# MSPM0G310X register map
Vendor: Texas Instruments; File version: This preliminary header file does not have a version number - build date: 2024-04-29 21:43:54
CPU: CM0 r0p1, little endian, MPU, no FPU, 3 interrupt priority bits
Registers are 32-bit, read-write, reset 0x0 unless marked. A register's access mark holds for its fields unless they carry their own. Offsets are from the block's base; [hi:lo] are bit positions; lines under a group give offsets from that group; {n}, {i} and the like mark numbered series; 'fields as' and 'values as' point back to an identical list.

## EVENTLP — PERIPHERALREGION
Base 0x400C9000
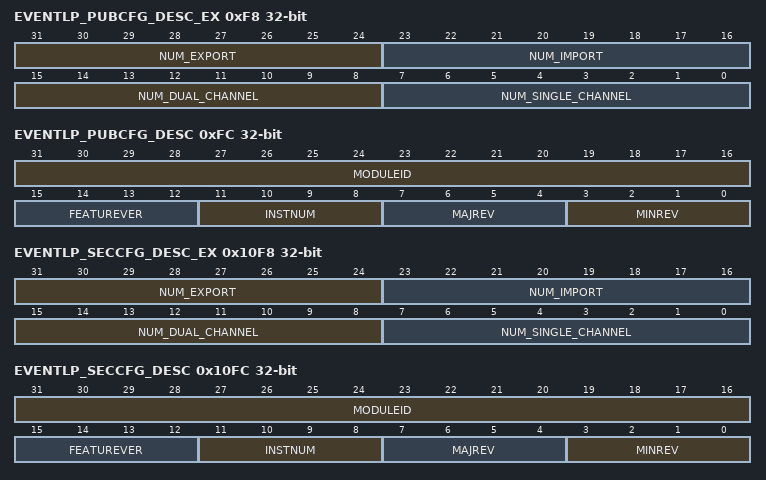
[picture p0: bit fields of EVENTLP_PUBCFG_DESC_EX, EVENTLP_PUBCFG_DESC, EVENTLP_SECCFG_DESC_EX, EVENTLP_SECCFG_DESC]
0xF8 EVENTLP_PUBCFG_DESC_EX ro — Extended Module Description
  [31:24] NUM_EXPORT — Number of export ports available in this EventManager instantiation
  [23:16] NUM_IMPORT — Number of import ports available in this EventManager instantiation
  [15:8] NUM_DUAL_CHANNEL — Number of dual channels contained in this instance of event manager
  [7:0] NUM_SINGLE_CHANNEL — Number of single channels contained in this instance of event manager
0xFC EVENTLP_PUBCFG_DESC ro — Module Description
  [31:16] MODULEID — Module identification contains a unique peripheral identification number. The assignments are maintained in a central database for all of the platform modules to ensure uniqueness.
  [15:12] FEATUREVER — Feature Set for the module *instance*
  [11:8] INSTNUM — Instance Number within the device. This will be a parameter to the RTL for modules that can have multiple instances
  [7:4] MAJREV — Major rev of the IP
  [3:0] MINREV — Minor rev of the IP
{0x100+0x80*i} EVENTLP_PUBCFG_FSUB[{i}] (i=0..0) group
  {0x0+4j} EVENTLP_PUBCFG_FSUB_PORT[{j}] (j=0..31) — Subscriber channel ID register
    [7:0] CHANID — Channel ID for subscriber to connect to
{0x300+0x68*i} EVENTLP_PUBCFG_FPUB[{i}] (i=0..0) group
  {0x0+4j} EVENTLP_PUBCFG_FPUB_PORT[{j}] (j=0..25) — Publisher channel ID register
    [7:0] CHANID — Channel ID for publisher to connect to
{0x500+4i} EVENTLP_PUBCFG_EXPORT[{i}] (i=0..0) group
  0x00 EVENTLP_PUBCFG_EXPORT_PORT — Export channel ID register
    [7:0] CHANID — Channel ID for export side to connect to
{0x700+4i} EVENTLP_PUBCFG_IMPORT[{i}] (i=0..0) group
  0x00 EVENTLP_PUBCFG_IMPORT_PORT — Import channel ID registe
    [7:0] CHANID — Channel ID for import side to connect to
{0x900+0x80*i} EVENTLP_PUBCFG_CPU_CONNECT[{i}] (i=0..0) group
  {0x0+4j} EVENTLP_PUBCFG_CPU_NUM[{j}] (j=0..31) — CPU connect register
    [1] CPUSS0_CONN — CPUSS0 connect bit.
      0=UNCONNECTED (The CPU is not connected.); 1=CONNECTED (The CPU is connected.)
0x10F8 EVENTLP_SECCFG_DESC_EX ro — Extended Module Description
  fields as EVENTLP_PUBCFG_DESC_EX
0x10FC EVENTLP_SECCFG_DESC ro — Module Description
  fields as EVENTLP_PUBCFG_DESC
{0x1100+0x20*i} EVENTLP_SECCFG_FSUB[{i}] (i=0..0) group
  {0x0+j} EVENTLP_SECCFG_FSUB_PORT[{j}] (j=0..31) 8-bit — Subscriber channel ID register
    [7:0] CHANID — Channel ID for subscriber to connect to
{0x1180+0x1A*i} EVENTLP_SECCFG_FPUB[{i}] (i=0..0) group
  {0x0+j} EVENTLP_SECCFG_FPUB_PORT[{j}] (j=0..25) 8-bit — Publisher channel ID register
    [7:0] CHANID — Channel ID for publisher to connect to
{0x1200+i} EVENTLP_SECCFG_EXPORT[{i}] (i=0..0) group
  0x00 EVENTLP_SECCFG_EXPORT_PORT 8-bit — Export channel ID register
    [7:0] CHANID — Channel ID for export side to connect to
{0x1280+i} EVENTLP_SECCFG_IMPORT[{i}] (i=0..0) group
  0x00 EVENTLP_SECCFG_IMPORT_PORT 8-bit — Import channel ID registe
    [7:0] CHANID — Channel ID for import side to connect to
{0x1300+0x20*i} EVENTLP_SECCFG_CPU_CONNECT[{i}] (i=0..0) group
  {0x0+j} EVENTLP_SECCFG_CPU_NUM[{j}] (j=0..31) 8-bit — CPU connect register
    fields as EVENTLP_PUBCFG_CPU_CONNECT[0].EVENTLP_PUBCFG_CPU_NUM[0]
0x1400 EVENTLP_CTL 8-bit — Event Manager control register
  [3:0] OVRWR_EN — Enable overwrite of config even if resources are already configured. By default, a configuration cannot be overwritten.
    5=DISABLE (Overwrite is disabled. Mode is same as in UNASG aperture.); 10=ENABLED (Ovewrite is enabled)
{0x1C00+0x400*i} EVENTLP_LMGMT_SFTYDIAG[{i}] (i=0..0) group
  0xEC EVENTLP_DIAGPAR192 wo — Diagnostic Parity Register 768
    [0] ASSERTDIAG — Writing a 1 will cause the safety diagnostic logic to generate a diagnostic check.
      0=NO_EFFECT; 1=START (Generate diagnostic check)
  0xF0 EVENTLP_DIAGPAR191 wo — Diagnostic Parity Register 191
    fields as EVENTLP_LMGMT_SFTYDIAG[0].EVENTLP_DIAGPAR192
  0xF4 EVENTLP_DIAGPAR190 wo — Diagnostic Parity Register 190
    fields as EVENTLP_LMGMT_SFTYDIAG[0].EVENTLP_DIAGPAR192
  0xF8 EVENTLP_DIAGPAR189 wo — Diagnostic Parity Register 189
    fields as EVENTLP_LMGMT_SFTYDIAG[0].EVENTLP_DIAGPAR192
  0xFC EVENTLP_DIAGPAR188 wo — Diagnostic Parity Register 188
    fields as EVENTLP_LMGMT_SFTYDIAG[0].EVENTLP_DIAGPAR192
  0x100 EVENTLP_DIAGPAR187 wo — Diagnostic Parity Register 187
    fields as EVENTLP_LMGMT_SFTYDIAG[0].EVENTLP_DIAGPAR192
  0x104 EVENTLP_DIAGPAR186 wo — Diagnostic Parity Register 186
    fields as EVENTLP_LMGMT_SFTYDIAG[0].EVENTLP_DIAGPAR192
  0x108 EVENTLP_DIAGPAR185 wo — Diagnostic Parity Register 185
    fields as EVENTLP_LMGMT_SFTYDIAG[0].EVENTLP_DIAGPAR192
  0x10C EVENTLP_DIAGPAR184 wo — Diagnostic Parity Register 184
    fields as EVENTLP_LMGMT_SFTYDIAG[0].EVENTLP_DIAGPAR192
  0x110 EVENTLP_DIAGPAR183 wo — Diagnostic Parity Register 183
    fields as EVENTLP_LMGMT_SFTYDIAG[0].EVENTLP_DIAGPAR192
  0x114 EVENTLP_DIAGPAR182 wo — Diagnostic Parity Register 182
    fields as EVENTLP_LMGMT_SFTYDIAG[0].EVENTLP_DIAGPAR192
  0x118 EVENTLP_DIAGPAR181 wo — Diagnostic Parity Register 181
    fields as EVENTLP_LMGMT_SFTYDIAG[0].EVENTLP_DIAGPAR192
  0x11C EVENTLP_DIAGPAR180 wo — Diagnostic Parity Register 180
    fields as EVENTLP_LMGMT_SFTYDIAG[0].EVENTLP_DIAGPAR192
  0x120 EVENTLP_DIAGPAR179 wo — Diagnostic Parity Register 179
    fields as EVENTLP_LMGMT_SFTYDIAG[0].EVENTLP_DIAGPAR192
  0x124 EVENTLP_DIAGPAR178 wo — Diagnostic Parity Register 178
    fields as EVENTLP_LMGMT_SFTYDIAG[0].EVENTLP_DIAGPAR192
  0x128 EVENTLP_DIAGPAR177 wo — Diagnostic Parity Register 177
    fields as EVENTLP_LMGMT_SFTYDIAG[0].EVENTLP_DIAGPAR192
  0x12C EVENTLP_DIAGPAR176 wo — Diagnostic Parity Register 176
    fields as EVENTLP_LMGMT_SFTYDIAG[0].EVENTLP_DIAGPAR192
  0x130 EVENTLP_DIAGPAR175 wo — Diagnostic Parity Register 175
    fields as EVENTLP_LMGMT_SFTYDIAG[0].EVENTLP_DIAGPAR192
  0x134 EVENTLP_DIAGPAR174 wo — Diagnostic Parity Register 174
    fields as EVENTLP_LMGMT_SFTYDIAG[0].EVENTLP_DIAGPAR192
  0x138 EVENTLP_DIAGPAR173 wo — Diagnostic Parity Register 173
    fields as EVENTLP_LMGMT_SFTYDIAG[0].EVENTLP_DIAGPAR192
  0x13C EVENTLP_DIAGPAR172 wo — Diagnostic Parity Register 172
    fields as EVENTLP_LMGMT_SFTYDIAG[0].EVENTLP_DIAGPAR192
  0x140 EVENTLP_DIAGPAR171 wo — Diagnostic Parity Register 171
    fields as EVENTLP_LMGMT_SFTYDIAG[0].EVENTLP_DIAGPAR192
  0x144 EVENTLP_DIAGPAR170 wo — Diagnostic Parity Register 170
    fields as EVENTLP_LMGMT_SFTYDIAG[0].EVENTLP_DIAGPAR192
  0x148 EVENTLP_DIAGPAR169 wo — Diagnostic Parity Register 169
    fields as EVENTLP_LMGMT_SFTYDIAG[0].EVENTLP_DIAGPAR192
  0x14C EVENTLP_DIAGPAR168 wo — Diagnostic Parity Register 168
    fields as EVENTLP_LMGMT_SFTYDIAG[0].EVENTLP_DIAGPAR192
  0x150 EVENTLP_DIAGPAR167 wo — Diagnostic Parity Register 167
    fields as EVENTLP_LMGMT_SFTYDIAG[0].EVENTLP_DIAGPAR192
  0x154 EVENTLP_DIAGPAR166 wo — Diagnostic Parity Register 166
    fields as EVENTLP_LMGMT_SFTYDIAG[0].EVENTLP_DIAGPAR192
  0x158 EVENTLP_DIAGPAR165 wo — Diagnostic Parity Register 165
    fields as EVENTLP_LMGMT_SFTYDIAG[0].EVENTLP_DIAGPAR192
  0x15C EVENTLP_DIAGPAR164 wo — Diagnostic Parity Register 164
    fields as EVENTLP_LMGMT_SFTYDIAG[0].EVENTLP_DIAGPAR192
  0x160 EVENTLP_DIAGPAR163 wo — Diagnostic Parity Register 163
    fields as EVENTLP_LMGMT_SFTYDIAG[0].EVENTLP_DIAGPAR192
  0x164 EVENTLP_DIAGPAR162 wo — Diagnostic Parity Register 162
    fields as EVENTLP_LMGMT_SFTYDIAG[0].EVENTLP_DIAGPAR192
  0x168 EVENTLP_DIAGPAR161 wo — Diagnostic Parity Register 161
    fields as EVENTLP_LMGMT_SFTYDIAG[0].EVENTLP_DIAGPAR192
  0x16C EVENTLP_DIAGPAR160 wo — Diagnostic Parity Register 160
    fields as EVENTLP_LMGMT_SFTYDIAG[0].EVENTLP_DIAGPAR192
  0x170 EVENTLP_DIAGPAR159 wo — Diagnostic Parity Register 159
    fields as EVENTLP_LMGMT_SFTYDIAG[0].EVENTLP_DIAGPAR192
  0x174 EVENTLP_DIAGPAR158 wo — Diagnostic Parity Register 158
    fields as EVENTLP_LMGMT_SFTYDIAG[0].EVENTLP_DIAGPAR192
  0x178 EVENTLP_DIAGPAR157 wo — Diagnostic Parity Register 157
    fields as EVENTLP_LMGMT_SFTYDIAG[0].EVENTLP_DIAGPAR192
  0x17C EVENTLP_DIAGPAR156 wo — Diagnostic Parity Register 156
    fields as EVENTLP_LMGMT_SFTYDIAG[0].EVENTLP_DIAGPAR192
  0x180 EVENTLP_DIAGPAR155 wo — Diagnostic Parity Register 155
    fields as EVENTLP_LMGMT_SFTYDIAG[0].EVENTLP_DIAGPAR192
  0x184 EVENTLP_DIAGPAR154 wo — Diagnostic Parity Register 154
    fields as EVENTLP_LMGMT_SFTYDIAG[0].EVENTLP_DIAGPAR192
  0x188 EVENTLP_DIAGPAR153 wo — Diagnostic Parity Register 153
    fields as EVENTLP_LMGMT_SFTYDIAG[0].EVENTLP_DIAGPAR192
  0x18C EVENTLP_DIAGPAR152 wo — Diagnostic Parity Register 152
    fields as EVENTLP_LMGMT_SFTYDIAG[0].EVENTLP_DIAGPAR192
  0x190 EVENTLP_DIAGPAR151 wo — Diagnostic Parity Register 151
    fields as EVENTLP_LMGMT_SFTYDIAG[0].EVENTLP_DIAGPAR192
  0x194 EVENTLP_DIAGPAR150 wo — Diagnostic Parity Register 150
    fields as EVENTLP_LMGMT_SFTYDIAG[0].EVENTLP_DIAGPAR192
  0x198 EVENTLP_DIAGPAR149 wo — Diagnostic Parity Register 149
    fields as EVENTLP_LMGMT_SFTYDIAG[0].EVENTLP_DIAGPAR192
  0x19C EVENTLP_DIAGPAR148 wo — Diagnostic Parity Register 148
    fields as EVENTLP_LMGMT_SFTYDIAG[0].EVENTLP_DIAGPAR192
  0x1A0 EVENTLP_DIAGPAR147 wo — Diagnostic Parity Register 147
    fields as EVENTLP_LMGMT_SFTYDIAG[0].EVENTLP_DIAGPAR192
  0x1A4 EVENTLP_DIAGPAR146 wo — Diagnostic Parity Register 146
    fields as EVENTLP_LMGMT_SFTYDIAG[0].EVENTLP_DIAGPAR192
  0x1A8 EVENTLP_DIAGPAR145 wo — Diagnostic Parity Register 145
    fields as EVENTLP_LMGMT_SFTYDIAG[0].EVENTLP_DIAGPAR192
  0x1AC EVENTLP_DIAGPAR144 wo — Diagnostic Parity Register 144
    fields as EVENTLP_LMGMT_SFTYDIAG[0].EVENTLP_DIAGPAR192
  0x1B0 EVENTLP_DIAGPAR143 wo — Diagnostic Parity Register 143
    fields as EVENTLP_LMGMT_SFTYDIAG[0].EVENTLP_DIAGPAR192
  0x1B4 EVENTLP_DIAGPAR142 wo — Diagnostic Parity Register 142
    fields as EVENTLP_LMGMT_SFTYDIAG[0].EVENTLP_DIAGPAR192
  0x1B8 EVENTLP_DIAGPAR141 wo — Diagnostic Parity Register 141
    fields as EVENTLP_LMGMT_SFTYDIAG[0].EVENTLP_DIAGPAR192
  0x1BC EVENTLP_DIAGPAR140 wo — Diagnostic Parity Register 140
    fields as EVENTLP_LMGMT_SFTYDIAG[0].EVENTLP_DIAGPAR192
  0x1C0 EVENTLP_DIAGPAR139 wo — Diagnostic Parity Register 139
    fields as EVENTLP_LMGMT_SFTYDIAG[0].EVENTLP_DIAGPAR192
  0x1C4 EVENTLP_DIAGPAR138 wo — Diagnostic Parity Register 138
    fields as EVENTLP_LMGMT_SFTYDIAG[0].EVENTLP_DIAGPAR192
  0x1C8 EVENTLP_DIAGPAR137 wo — Diagnostic Parity Register 137
    fields as EVENTLP_LMGMT_SFTYDIAG[0].EVENTLP_DIAGPAR192
  0x1CC EVENTLP_DIAGPAR136 wo — Diagnostic Parity Register 136
    fields as EVENTLP_LMGMT_SFTYDIAG[0].EVENTLP_DIAGPAR192
  0x1D0 EVENTLP_DIAGPAR135 wo — Diagnostic Parity Register 135
    fields as EVENTLP_LMGMT_SFTYDIAG[0].EVENTLP_DIAGPAR192
  0x1D4 EVENTLP_DIAGPAR134 wo — Diagnostic Parity Register 134
    fields as EVENTLP_LMGMT_SFTYDIAG[0].EVENTLP_DIAGPAR192
  0x1D8 EVENTLP_DIAGPAR133 wo — Diagnostic Parity Register 133
    fields as EVENTLP_LMGMT_SFTYDIAG[0].EVENTLP_DIAGPAR192
  0x1DC EVENTLP_DIAGPAR132 wo — Diagnostic Parity Register 132
    fields as EVENTLP_LMGMT_SFTYDIAG[0].EVENTLP_DIAGPAR192
  0x1E0 EVENTLP_DIAGPAR131 wo — Diagnostic Parity Register 131
    fields as EVENTLP_LMGMT_SFTYDIAG[0].EVENTLP_DIAGPAR192
  0x1E4 EVENTLP_DIAGPAR130 wo — Diagnostic Parity Register 130
    fields as EVENTLP_LMGMT_SFTYDIAG[0].EVENTLP_DIAGPAR192
  0x1E8 EVENTLP_DIAGPAR129 wo — Diagnostic Parity Register 129
    fields as EVENTLP_LMGMT_SFTYDIAG[0].EVENTLP_DIAGPAR192
  0x1EC EVENTLP_DIAGPAR128 wo — Diagnostic Parity Register 128
    fields as EVENTLP_LMGMT_SFTYDIAG[0].EVENTLP_DIAGPAR192
  0x1F0 EVENTLP_DIAGPAR127 wo — Diagnostic Parity Register 127
    fields as EVENTLP_LMGMT_SFTYDIAG[0].EVENTLP_DIAGPAR192
  0x1F4 EVENTLP_DIAGPAR126 wo — Diagnostic Parity Register 126
    fields as EVENTLP_LMGMT_SFTYDIAG[0].EVENTLP_DIAGPAR192
  0x1F8 EVENTLP_DIAGPAR125 wo — Diagnostic Parity Register 125
    fields as EVENTLP_LMGMT_SFTYDIAG[0].EVENTLP_DIAGPAR192
  0x1FC EVENTLP_DIAGPAR124 wo — Diagnostic Parity Register 124
    fields as EVENTLP_LMGMT_SFTYDIAG[0].EVENTLP_DIAGPAR192
  0x200 EVENTLP_DIAGPAR123 wo — Diagnostic Parity Register 123
    fields as EVENTLP_LMGMT_SFTYDIAG[0].EVENTLP_DIAGPAR192
  0x204 EVENTLP_DIAGPAR122 wo — Diagnostic Parity Register 122
    fields as EVENTLP_LMGMT_SFTYDIAG[0].EVENTLP_DIAGPAR192
  0x208 EVENTLP_DIAGPAR121 wo — Diagnostic Parity Register 121
    fields as EVENTLP_LMGMT_SFTYDIAG[0].EVENTLP_DIAGPAR192
  0x20C EVENTLP_DIAGPAR120 wo — Diagnostic Parity Register 120
    fields as EVENTLP_LMGMT_SFTYDIAG[0].EVENTLP_DIAGPAR192
  0x210 EVENTLP_DIAGPAR119 wo — Diagnostic Parity Register 119
    fields as EVENTLP_LMGMT_SFTYDIAG[0].EVENTLP_DIAGPAR192
  0x214 EVENTLP_DIAGPAR118 wo — Diagnostic Parity Register 118
    fields as EVENTLP_LMGMT_SFTYDIAG[0].EVENTLP_DIAGPAR192
  0x218 EVENTLP_DIAGPAR117 wo — Diagnostic Parity Register 117
    fields as EVENTLP_LMGMT_SFTYDIAG[0].EVENTLP_DIAGPAR192
  0x21C EVENTLP_DIAGPAR116 wo — Diagnostic Parity Register 116
    fields as EVENTLP_LMGMT_SFTYDIAG[0].EVENTLP_DIAGPAR192
  0x220 EVENTLP_DIAGPAR115 wo — Diagnostic Parity Register 115
    fields as EVENTLP_LMGMT_SFTYDIAG[0].EVENTLP_DIAGPAR192
  0x224 EVENTLP_DIAGPAR114 wo — Diagnostic Parity Register 114
    fields as EVENTLP_LMGMT_SFTYDIAG[0].EVENTLP_DIAGPAR192
  0x228 EVENTLP_DIAGPAR113 wo — Diagnostic Parity Register 113
    fields as EVENTLP_LMGMT_SFTYDIAG[0].EVENTLP_DIAGPAR192
  0x22C EVENTLP_DIAGPAR112 wo — Diagnostic Parity Register 112
    fields as EVENTLP_LMGMT_SFTYDIAG[0].EVENTLP_DIAGPAR192
  0x230 EVENTLP_DIAGPAR111 wo — Diagnostic Parity Register 111
    fields as EVENTLP_LMGMT_SFTYDIAG[0].EVENTLP_DIAGPAR192
  0x234 EVENTLP_DIAGPAR110 wo — Diagnostic Parity Register 110
    fields as EVENTLP_LMGMT_SFTYDIAG[0].EVENTLP_DIAGPAR192
  0x238 EVENTLP_DIAGPAR109 wo — Diagnostic Parity Register 109
    fields as EVENTLP_LMGMT_SFTYDIAG[0].EVENTLP_DIAGPAR192
  0x23C EVENTLP_DIAGPAR108 wo — Diagnostic Parity Register 108
    fields as EVENTLP_LMGMT_SFTYDIAG[0].EVENTLP_DIAGPAR192
  0x240 EVENTLP_DIAGPAR107 wo — Diagnostic Parity Register 107
    fields as EVENTLP_LMGMT_SFTYDIAG[0].EVENTLP_DIAGPAR192
  0x244 EVENTLP_DIAGPAR106 wo — Diagnostic Parity Register 106
    fields as EVENTLP_LMGMT_SFTYDIAG[0].EVENTLP_DIAGPAR192
  0x248 EVENTLP_DIAGPAR105 wo — Diagnostic Parity Register 105
    fields as EVENTLP_LMGMT_SFTYDIAG[0].EVENTLP_DIAGPAR192
  0x24C EVENTLP_DIAGPAR104 wo — Diagnostic Parity Register 104
    fields as EVENTLP_LMGMT_SFTYDIAG[0].EVENTLP_DIAGPAR192
  0x250 EVENTLP_DIAGPAR103 wo — Diagnostic Parity Register 103
    fields as EVENTLP_LMGMT_SFTYDIAG[0].EVENTLP_DIAGPAR192
  0x254 EVENTLP_DIAGPAR102 wo — Diagnostic Parity Register 102
    fields as EVENTLP_LMGMT_SFTYDIAG[0].EVENTLP_DIAGPAR192
  0x258 EVENTLP_DIAGPAR101 wo — Diagnostic Parity Register 101
    fields as EVENTLP_LMGMT_SFTYDIAG[0].EVENTLP_DIAGPAR192
  0x25C EVENTLP_DIAGPAR100 wo — Diagnostic Parity Register 100
    fields as EVENTLP_LMGMT_SFTYDIAG[0].EVENTLP_DIAGPAR192
  0x260 EVENTLP_DIAGPAR99 wo — Diagnostic Parity Register 99
    fields as EVENTLP_LMGMT_SFTYDIAG[0].EVENTLP_DIAGPAR192
  0x264 EVENTLP_DIAGPAR98 wo — Diagnostic Parity Register 98
    fields as EVENTLP_LMGMT_SFTYDIAG[0].EVENTLP_DIAGPAR192
  0x268 EVENTLP_DIAGPAR97 wo — Diagnostic Parity Register 97
    fields as EVENTLP_LMGMT_SFTYDIAG[0].EVENTLP_DIAGPAR192
  0x26C EVENTLP_DIAGPAR96 wo — Diagnostic Parity Register 96
    fields as EVENTLP_LMGMT_SFTYDIAG[0].EVENTLP_DIAGPAR192
  0x270 EVENTLP_DIAGPAR95 wo — Diagnostic Parity Register 95
    fields as EVENTLP_LMGMT_SFTYDIAG[0].EVENTLP_DIAGPAR192
  0x274 EVENTLP_DIAGPAR94 wo — Diagnostic Parity Register 94
    fields as EVENTLP_LMGMT_SFTYDIAG[0].EVENTLP_DIAGPAR192
  0x278 EVENTLP_DIAGPAR93 wo — Diagnostic Parity Register 93
    fields as EVENTLP_LMGMT_SFTYDIAG[0].EVENTLP_DIAGPAR192
  0x27C EVENTLP_DIAGPAR92 wo — Diagnostic Parity Register 92
    fields as EVENTLP_LMGMT_SFTYDIAG[0].EVENTLP_DIAGPAR192
  0x280 EVENTLP_DIAGPAR91 wo — Diagnostic Parity Register 91
    fields as EVENTLP_LMGMT_SFTYDIAG[0].EVENTLP_DIAGPAR192
  0x284 EVENTLP_DIAGPAR90 wo — Diagnostic Parity Register 90
    fields as EVENTLP_LMGMT_SFTYDIAG[0].EVENTLP_DIAGPAR192
  0x288 EVENTLP_DIAGPAR89 wo — Diagnostic Parity Register 89
    fields as EVENTLP_LMGMT_SFTYDIAG[0].EVENTLP_DIAGPAR192
  0x28C EVENTLP_DIAGPAR88 wo — Diagnostic Parity Register 88
    fields as EVENTLP_LMGMT_SFTYDIAG[0].EVENTLP_DIAGPAR192
  0x290 EVENTLP_DIAGPAR87 wo — Diagnostic Parity Register 87
    fields as EVENTLP_LMGMT_SFTYDIAG[0].EVENTLP_DIAGPAR192
  0x294 EVENTLP_DIAGPAR86 wo — Diagnostic Parity Register 86
    fields as EVENTLP_LMGMT_SFTYDIAG[0].EVENTLP_DIAGPAR192
  0x298 EVENTLP_DIAGPAR85 wo — Diagnostic Parity Register 85
    fields as EVENTLP_LMGMT_SFTYDIAG[0].EVENTLP_DIAGPAR192
  0x29C EVENTLP_DIAGPAR84 wo — Diagnostic Parity Register 84
    fields as EVENTLP_LMGMT_SFTYDIAG[0].EVENTLP_DIAGPAR192
  0x2A0 EVENTLP_DIAGPAR83 wo — Diagnostic Parity Register 83
    fields as EVENTLP_LMGMT_SFTYDIAG[0].EVENTLP_DIAGPAR192
  0x2A4 EVENTLP_DIAGPAR82 wo — Diagnostic Parity Register 82
    fields as EVENTLP_LMGMT_SFTYDIAG[0].EVENTLP_DIAGPAR192
  0x2A8 EVENTLP_DIAGPAR81 wo — Diagnostic Parity Register 81
    fields as EVENTLP_LMGMT_SFTYDIAG[0].EVENTLP_DIAGPAR192
  0x2AC EVENTLP_DIAGPAR80 wo — Diagnostic Parity Register 80
    fields as EVENTLP_LMGMT_SFTYDIAG[0].EVENTLP_DIAGPAR192
  0x2B0 EVENTLP_DIAGPAR79 wo — Diagnostic Parity Register 79
    fields as EVENTLP_LMGMT_SFTYDIAG[0].EVENTLP_DIAGPAR192
  0x2B4 EVENTLP_DIAGPAR78 wo — Diagnostic Parity Register 78
    fields as EVENTLP_LMGMT_SFTYDIAG[0].EVENTLP_DIAGPAR192
  0x2B8 EVENTLP_DIAGPAR77 wo — Diagnostic Parity Register 77
    fields as EVENTLP_LMGMT_SFTYDIAG[0].EVENTLP_DIAGPAR192
  0x2BC EVENTLP_DIAGPAR76 wo — Diagnostic Parity Register 76
    fields as EVENTLP_LMGMT_SFTYDIAG[0].EVENTLP_DIAGPAR192
  0x2C0 EVENTLP_DIAGPAR75 wo — Diagnostic Parity Register 75
    fields as EVENTLP_LMGMT_SFTYDIAG[0].EVENTLP_DIAGPAR192
  0x2C4 EVENTLP_DIAGPAR74 wo — Diagnostic Parity Register 74
    fields as EVENTLP_LMGMT_SFTYDIAG[0].EVENTLP_DIAGPAR192
  0x2C8 EVENTLP_DIAGPAR73 wo — Diagnostic Parity Register 73
    fields as EVENTLP_LMGMT_SFTYDIAG[0].EVENTLP_DIAGPAR192
  0x2CC EVENTLP_DIAGPAR72 wo — Diagnostic Parity Register 72
    fields as EVENTLP_LMGMT_SFTYDIAG[0].EVENTLP_DIAGPAR192
  0x2D0 EVENTLP_DIAGPAR71 wo — Diagnostic Parity Register 71
    fields as EVENTLP_LMGMT_SFTYDIAG[0].EVENTLP_DIAGPAR192
  0x2D4 EVENTLP_DIAGPAR70 wo — Diagnostic Parity Register 70
    fields as EVENTLP_LMGMT_SFTYDIAG[0].EVENTLP_DIAGPAR192
  0x2D8 EVENTLP_DIAGPAR69 wo — Diagnostic Parity Register 69
    fields as EVENTLP_LMGMT_SFTYDIAG[0].EVENTLP_DIAGPAR192
  0x2DC EVENTLP_DIAGPAR68 wo — Diagnostic Parity Register 68
    fields as EVENTLP_LMGMT_SFTYDIAG[0].EVENTLP_DIAGPAR192
  0x2E0 EVENTLP_DIAGPAR67 wo — Diagnostic Parity Register 67
    fields as EVENTLP_LMGMT_SFTYDIAG[0].EVENTLP_DIAGPAR192
  0x2E4 EVENTLP_DIAGPAR66 wo — Diagnostic Parity Register 66
    fields as EVENTLP_LMGMT_SFTYDIAG[0].EVENTLP_DIAGPAR192
  0x2E8 EVENTLP_DIAGPAR65 wo — Diagnostic Parity Register 65
    fields as EVENTLP_LMGMT_SFTYDIAG[0].EVENTLP_DIAGPAR192
  0x2EC EVENTLP_DIAGPAR64 wo — Diagnostic Parity Register 64
    fields as EVENTLP_LMGMT_SFTYDIAG[0].EVENTLP_DIAGPAR192
  0x2F0 EVENTLP_DIAGPAR63 wo — Diagnostic Parity Register 63
    fields as EVENTLP_LMGMT_SFTYDIAG[0].EVENTLP_DIAGPAR192
  0x2F4 EVENTLP_DIAGPAR62 wo — Diagnostic Parity Register 62
    fields as EVENTLP_LMGMT_SFTYDIAG[0].EVENTLP_DIAGPAR192
  0x2F8 EVENTLP_DIAGPAR61 wo — Diagnostic Parity Register 61
    fields as EVENTLP_LMGMT_SFTYDIAG[0].EVENTLP_DIAGPAR192
  0x2FC EVENTLP_DIAGPAR60 wo — Diagnostic Parity Register 60
    fields as EVENTLP_LMGMT_SFTYDIAG[0].EVENTLP_DIAGPAR192
  0x300 EVENTLP_DIAGPAR59 wo — Diagnostic Parity Register 59
    fields as EVENTLP_LMGMT_SFTYDIAG[0].EVENTLP_DIAGPAR192
  0x304 EVENTLP_DIAGPAR58 wo — Diagnostic Parity Register 58
    fields as EVENTLP_LMGMT_SFTYDIAG[0].EVENTLP_DIAGPAR192
  0x308 EVENTLP_DIAGPAR57 wo — Diagnostic Parity Register 57
    fields as EVENTLP_LMGMT_SFTYDIAG[0].EVENTLP_DIAGPAR192
  0x30C EVENTLP_DIAGPAR56 wo — Diagnostic Parity Register 56
    fields as EVENTLP_LMGMT_SFTYDIAG[0].EVENTLP_DIAGPAR192
  0x310 EVENTLP_DIAGPAR55 wo — Diagnostic Parity Register 55
    fields as EVENTLP_LMGMT_SFTYDIAG[0].EVENTLP_DIAGPAR192
  0x314 EVENTLP_DIAGPAR54 wo — Diagnostic Parity Register 54
    fields as EVENTLP_LMGMT_SFTYDIAG[0].EVENTLP_DIAGPAR192
  0x318 EVENTLP_DIAGPAR53 wo — Diagnostic Parity Register 53
    fields as EVENTLP_LMGMT_SFTYDIAG[0].EVENTLP_DIAGPAR192
  0x31C EVENTLP_DIAGPAR52 wo — Diagnostic Parity Register 52
    fields as EVENTLP_LMGMT_SFTYDIAG[0].EVENTLP_DIAGPAR192
  0x320 EVENTLP_DIAGPAR51 wo — Diagnostic Parity Register 51
    fields as EVENTLP_LMGMT_SFTYDIAG[0].EVENTLP_DIAGPAR192
  0x324 EVENTLP_DIAGPAR50 wo — Diagnostic Parity Register 50
    fields as EVENTLP_LMGMT_SFTYDIAG[0].EVENTLP_DIAGPAR192
  0x328 EVENTLP_DIAGPAR49 wo — Diagnostic Parity Register 49
    fields as EVENTLP_LMGMT_SFTYDIAG[0].EVENTLP_DIAGPAR192
  0x32C EVENTLP_DIAGPAR48 wo — Diagnostic Parity Register 48
    fields as EVENTLP_LMGMT_SFTYDIAG[0].EVENTLP_DIAGPAR192
  0x330 EVENTLP_DIAGPAR47 wo — Diagnostic Parity Register 47
    fields as EVENTLP_LMGMT_SFTYDIAG[0].EVENTLP_DIAGPAR192
  0x334 EVENTLP_DIAGPAR46 wo — Diagnostic Parity Register 46
    fields as EVENTLP_LMGMT_SFTYDIAG[0].EVENTLP_DIAGPAR192
  0x338 EVENTLP_DIAGPAR45 wo — Diagnostic Parity Register 45
    fields as EVENTLP_LMGMT_SFTYDIAG[0].EVENTLP_DIAGPAR192
  0x33C EVENTLP_DIAGPAR44 wo — Diagnostic Parity Register 44
    fields as EVENTLP_LMGMT_SFTYDIAG[0].EVENTLP_DIAGPAR192
  0x340 EVENTLP_DIAGPAR43 wo — Diagnostic Parity Register 43
    fields as EVENTLP_LMGMT_SFTYDIAG[0].EVENTLP_DIAGPAR192
  0x344 EVENTLP_DIAGPAR42 wo — Diagnostic Parity Register 42
    fields as EVENTLP_LMGMT_SFTYDIAG[0].EVENTLP_DIAGPAR192
  0x348 EVENTLP_DIAGPAR41 wo — Diagnostic Parity Register 41
    fields as EVENTLP_LMGMT_SFTYDIAG[0].EVENTLP_DIAGPAR192
  0x34C EVENTLP_DIAGPAR40 wo — Diagnostic Parity Register 40
    fields as EVENTLP_LMGMT_SFTYDIAG[0].EVENTLP_DIAGPAR192
  0x350 EVENTLP_DIAGPAR39 wo — Diagnostic Parity Register 39
    fields as EVENTLP_LMGMT_SFTYDIAG[0].EVENTLP_DIAGPAR192
  0x354 EVENTLP_DIAGPAR38 wo — Diagnostic Parity Register 38
    fields as EVENTLP_LMGMT_SFTYDIAG[0].EVENTLP_DIAGPAR192
  0x358 EVENTLP_DIAGPAR37 wo — Diagnostic Parity Register 37
    fields as EVENTLP_LMGMT_SFTYDIAG[0].EVENTLP_DIAGPAR192
  0x35C EVENTLP_DIAGPAR36 wo — Diagnostic Parity Register 36
    fields as EVENTLP_LMGMT_SFTYDIAG[0].EVENTLP_DIAGPAR192
  0x360 EVENTLP_DIAGPAR35 wo — Diagnostic Parity Register 35
    fields as EVENTLP_LMGMT_SFTYDIAG[0].EVENTLP_DIAGPAR192
  0x364 EVENTLP_DIAGPAR34 wo — Diagnostic Parity Register 34
    fields as EVENTLP_LMGMT_SFTYDIAG[0].EVENTLP_DIAGPAR192
  0x368 EVENTLP_DIAGPAR33 wo — Diagnostic Parity Register 33
    fields as EVENTLP_LMGMT_SFTYDIAG[0].EVENTLP_DIAGPAR192
  0x36C EVENTLP_DIAGPAR32 wo — Diagnostic Parity Register 32
    fields as EVENTLP_LMGMT_SFTYDIAG[0].EVENTLP_DIAGPAR192
  0x370 EVENTLP_DIAGPAR31 wo — Diagnostic Parity Register 31
    fields as EVENTLP_LMGMT_SFTYDIAG[0].EVENTLP_DIAGPAR192
  0x374 EVENTLP_DIAGPAR30 wo — Diagnostic Parity Register 30
    fields as EVENTLP_LMGMT_SFTYDIAG[0].EVENTLP_DIAGPAR192
  0x378 EVENTLP_DIAGPAR29 wo — Diagnostic Parity Register 29
    fields as EVENTLP_LMGMT_SFTYDIAG[0].EVENTLP_DIAGPAR192
  0x37C EVENTLP_DIAGPAR28 wo — Diagnostic Parity Register 28
    fields as EVENTLP_LMGMT_SFTYDIAG[0].EVENTLP_DIAGPAR192
  0x380 EVENTLP_DIAGPAR27 wo — Diagnostic Parity Register 27
    fields as EVENTLP_LMGMT_SFTYDIAG[0].EVENTLP_DIAGPAR192
  0x384 EVENTLP_DIAGPAR26 wo — Diagnostic Parity Register 26
    fields as EVENTLP_LMGMT_SFTYDIAG[0].EVENTLP_DIAGPAR192
  0x388 EVENTLP_DIAGPAR25 wo — Diagnostic Parity Register 25
    fields as EVENTLP_LMGMT_SFTYDIAG[0].EVENTLP_DIAGPAR192
  0x38C EVENTLP_DIAGPAR24 wo — Diagnostic Parity Register 24
    fields as EVENTLP_LMGMT_SFTYDIAG[0].EVENTLP_DIAGPAR192
  0x390 EVENTLP_DIAGPAR23 wo — Diagnostic Parity Register 23
    fields as EVENTLP_LMGMT_SFTYDIAG[0].EVENTLP_DIAGPAR192
  0x394 EVENTLP_DIAGPAR22 wo — Diagnostic Parity Register 22
    fields as EVENTLP_LMGMT_SFTYDIAG[0].EVENTLP_DIAGPAR192
  0x398 EVENTLP_DIAGPAR21 wo — Diagnostic Parity Register 21
    fields as EVENTLP_LMGMT_SFTYDIAG[0].EVENTLP_DIAGPAR192
  0x39C EVENTLP_DIAGPAR20 wo — Diagnostic Parity Register 20
    fields as EVENTLP_LMGMT_SFTYDIAG[0].EVENTLP_DIAGPAR192
  0x3A0 EVENTLP_DIAGPAR19 wo — Diagnostic Parity Register 19
    fields as EVENTLP_LMGMT_SFTYDIAG[0].EVENTLP_DIAGPAR192
  0x3A4 EVENTLP_DIAGPAR18 wo — Diagnostic Parity Register 18
    fields as EVENTLP_LMGMT_SFTYDIAG[0].EVENTLP_DIAGPAR192
  0x3A8 EVENTLP_DIAGPAR17 wo — Diagnostic Parity Register 17
    fields as EVENTLP_LMGMT_SFTYDIAG[0].EVENTLP_DIAGPAR192
  0x3AC EVENTLP_DIAGPAR16 wo — Diagnostic Parity Register 16
    fields as EVENTLP_LMGMT_SFTYDIAG[0].EVENTLP_DIAGPAR192
  0x3B0 EVENTLP_DIAGPAR15 wo — Diagnostic Parity Register 15
    fields as EVENTLP_LMGMT_SFTYDIAG[0].EVENTLP_DIAGPAR192
  0x3B4 EVENTLP_DIAGPAR14 wo — Diagnostic Parity Register 14
    fields as EVENTLP_LMGMT_SFTYDIAG[0].EVENTLP_DIAGPAR192
  0x3B8 EVENTLP_DIAGPAR13 wo — Diagnostic Parity Register 13
    fields as EVENTLP_LMGMT_SFTYDIAG[0].EVENTLP_DIAGPAR192
  0x3BC EVENTLP_DIAGPAR12 wo — Diagnostic Parity Register 12
    fields as EVENTLP_LMGMT_SFTYDIAG[0].EVENTLP_DIAGPAR192
  0x3C0 EVENTLP_DIAGPAR11 wo — Diagnostic Parity Register 11
    fields as EVENTLP_LMGMT_SFTYDIAG[0].EVENTLP_DIAGPAR192
  0x3C4 EVENTLP_DIAGPAR10 wo — Diagnostic Parity Register 10
    fields as EVENTLP_LMGMT_SFTYDIAG[0].EVENTLP_DIAGPAR192
  0x3C8 EVENTLP_DIAGPAR9 wo — Diagnostic Parity Register 9
    fields as EVENTLP_LMGMT_SFTYDIAG[0].EVENTLP_DIAGPAR192
  0x3CC EVENTLP_DIAGPAR8 wo — Diagnostic Parity Register 8
    fields as EVENTLP_LMGMT_SFTYDIAG[0].EVENTLP_DIAGPAR192
  0x3D0 EVENTLP_DIAGPAR7 wo — Diagnostic Parity Register 7
    fields as EVENTLP_LMGMT_SFTYDIAG[0].EVENTLP_DIAGPAR192
  0x3D4 EVENTLP_DIAGPAR6 wo — Diagnostic Parity Register 6
    fields as EVENTLP_LMGMT_SFTYDIAG[0].EVENTLP_DIAGPAR192
  0x3D8 EVENTLP_DIAGPAR5 wo — Diagnostic Parity Register 5
    fields as EVENTLP_LMGMT_SFTYDIAG[0].EVENTLP_DIAGPAR192
  0x3DC EVENTLP_DIAGPAR4 wo — Diagnostic Parity Register 4
    fields as EVENTLP_LMGMT_SFTYDIAG[0].EVENTLP_DIAGPAR192
  0x3E0 EVENTLP_DIAGPAR3 wo — Diagnostic Parity Register 3
    fields as EVENTLP_LMGMT_SFTYDIAG[0].EVENTLP_DIAGPAR192
  0x3E4 EVENTLP_DIAGPAR2 wo — Diagnostic Parity Register 2
    fields as EVENTLP_LMGMT_SFTYDIAG[0].EVENTLP_DIAGPAR192
  0x3E8 EVENTLP_DIAGPAR1 wo — Diagnostic Parity Register 1
    fields as EVENTLP_LMGMT_SFTYDIAG[0].EVENTLP_DIAGPAR192
  0x3EC EVENTLP_DIAGPAR0 wo — Diagnostic Parity Register 0
    fields as EVENTLP_LMGMT_SFTYDIAG[0].EVENTLP_DIAGPAR192
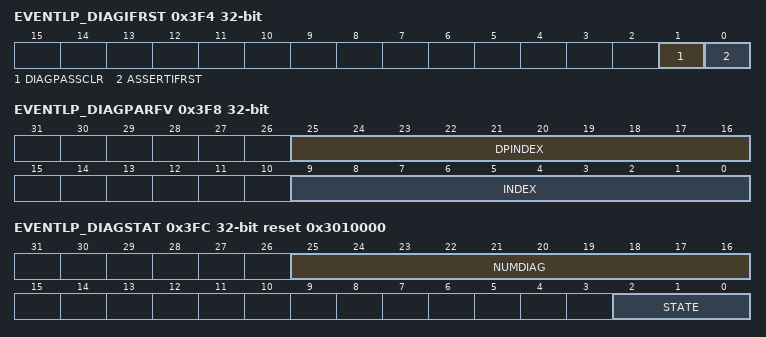
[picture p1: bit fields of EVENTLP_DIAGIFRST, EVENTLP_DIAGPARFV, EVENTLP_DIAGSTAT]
  0x3F4 EVENTLP_DIAGIFRST — Diagnostic Interface Reset Register
    [1] DIAGPASSCLR wo — Writing a 1 will synchronously clear the PARFV MMR DPINDEX field. The STICKY bit for DIAGPASS status will be cleared as well.
      0=NO_EFFECT; 1=CLR (Clear)
    [0] ASSERTIFRST wo — Writing a 1 will synchronously clear the Diagnostic Interface. The STICKY bits for status and well as the PARFV will be cleared. If a true functional failure still exists, the interface will re-assert FUNCFAIL on the cycle following the interface reset
      0=NO_EFFECT; 1=CLR (Clear)
  0x3F8 EVENTLP_DIAGPARFV ro — Diagnostic Parity Fail Vector Register
    [25:16] DPINDEX — Index of DIAG PASS MMR. NOTE: DPINDEX value of 1 corresponds to DIAGPAR0, 2 corresponds to DIAGPAR1 and so on.
    [9:0] INDEX — Index of DIAG MMR creating the failure. NOTE: INDEX value of 1 corresponds to DIAGPAR0, 2 corresponds to DIAGPAR1 and so on.
  0x3FC EVENTLP_DIAGSTAT ro reset 0x3010000 — Diagnostic Status Register
    [25:16] NUMDIAG — This is a hardware constant that indicates how many DIAGPAR registers are included in this SFTYDIAG sub-region.
    [2:0] STATE — Current diagnostic state
      0=NONE (No failures and no diagnostic); 1=FUNC_FAIL (Functional Failure); 2=DIAG_FAIL (Diagnostic Failure); 4=DIAG_PASS (Diagnostic Pass)
{0x2000+4i} EVENTLP_IMPEXPCFG_EXPORT[{i}] (i=0..0) group
  0x00 EVENTLP_IMPEXPCFG_EXPORT_PORT — Export channel ID register
    [7:0] CHANID — Channel ID for import side to connect to
{0x2200+4i} EVENTLP_IMPEXPCFG_IMPORT[{i}] (i=0..0) group
  0x00 EVENTLP_IMPEXPCFG_IMPORT_PORT — Import channel ID registe
    [7:0] CHANID — Channel ID for import side to connect to
